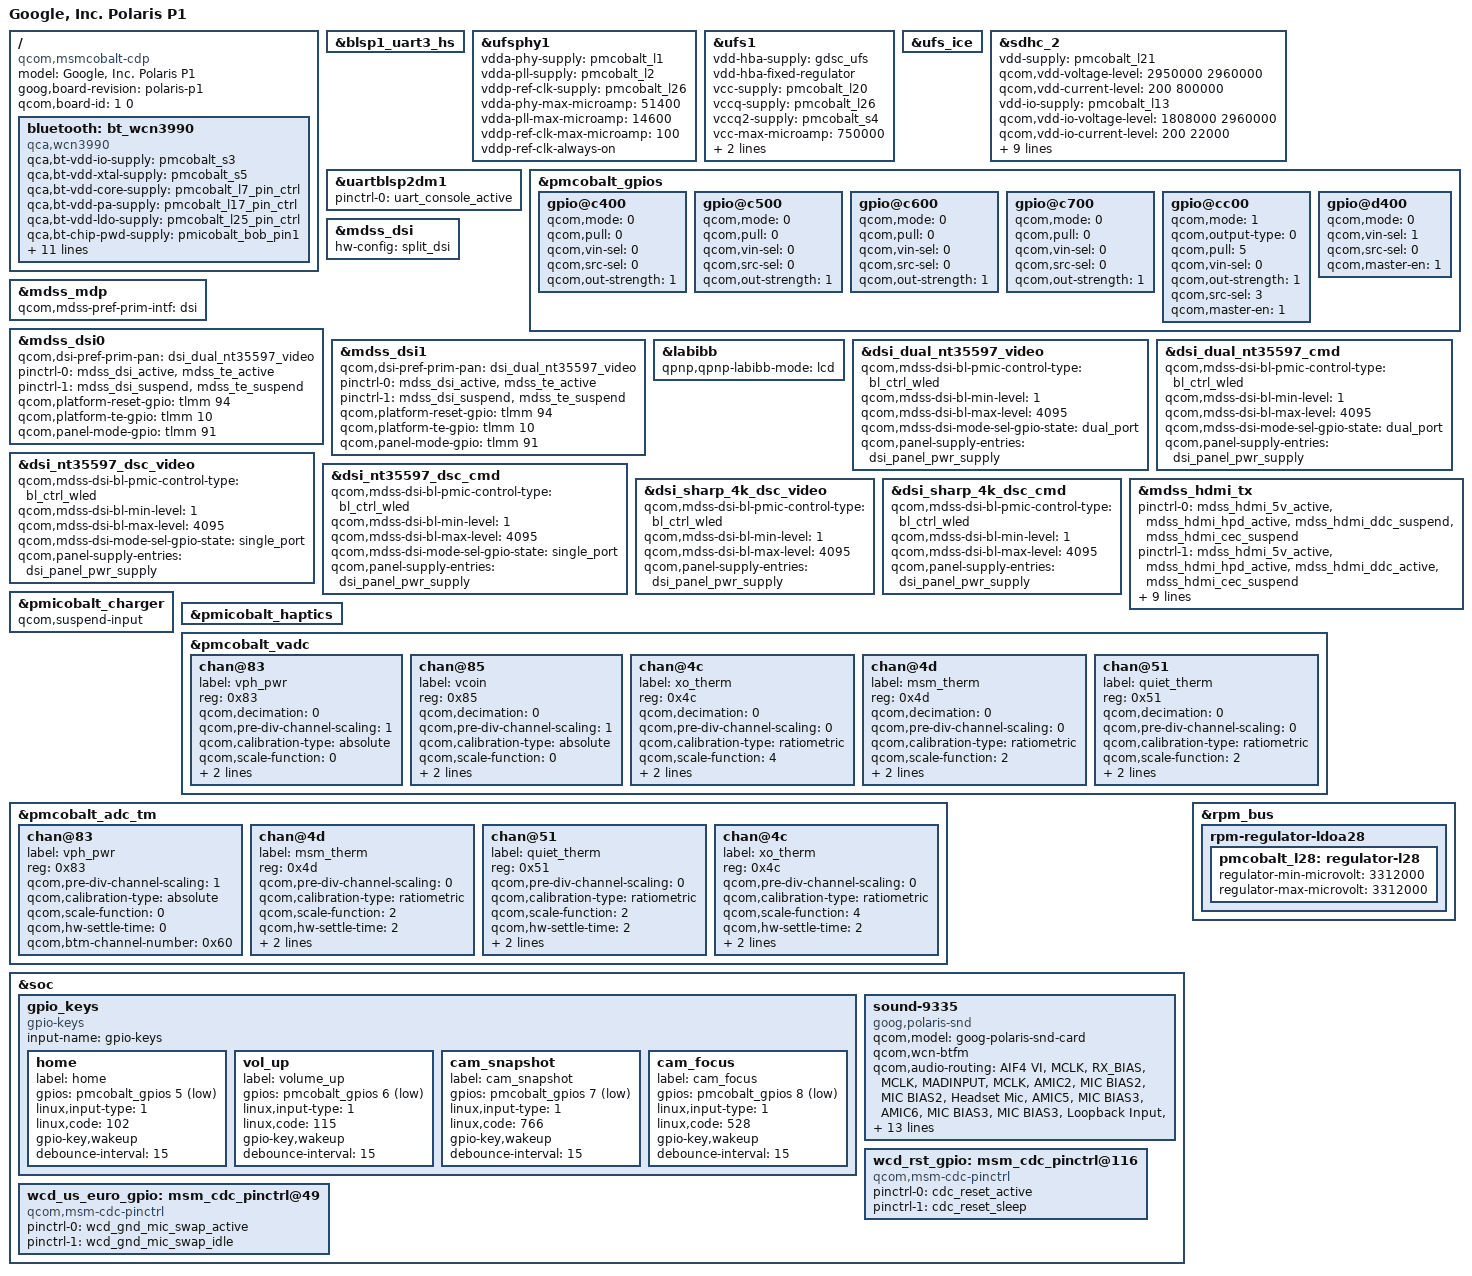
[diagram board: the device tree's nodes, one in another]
/* Copyright (c) 2016, The Linux Foundation. All rights reserved.
 *
 * This program is free software; you can redistribute it and/or modify
 * it under the terms of the GNU General Public License version 2 and
 * only version 2 as published by the Free Software Foundation.
 *
 * This program is distributed in the hope that it will be useful,
 * but WITHOUT ANY WARRANTY; without even the implied warranty of
 * MERCHANTABILITY or FITNESS FOR A PARTICULAR PURPOSE.  See the
 * GNU General Public License for more details.
 */

/dts-v1/;

#include <dt-bindings/gpio/gpio.h>
#include <dt-bindings/input/input.h>

#include "../qcom/msmcobalt.dtsi"
#include "../qcom/msmcobalt-camera-sensor-cdp.dtsi"

#include "polaris-pinctrl.dtsi"

/ {
	model = "Google, Inc. Polaris P1";
	/* compatible = "goog,polaris", "goog,polaris-p1"; */
	goog,board-revision = "polaris-p1";

	/* TODO(muirj): Remove once the boot-loader can select based
	 * on the above information only. */
	compatible = "qcom,msmcobalt-cdp", "qcom,msmcobalt", "qcom,cdp";
	qcom,board-id = <1 0>;
};

/ {
	bluetooth: bt_wcn3990 {
		compatible = "qca,wcn3990";
		qca,bt-vdd-io-supply = <&pmcobalt_s3>;
		qca,bt-vdd-xtal-supply = <&pmcobalt_s5>;
		qca,bt-vdd-core-supply = <&pmcobalt_l7_pin_ctrl>;
		qca,bt-vdd-pa-supply = <&pmcobalt_l17_pin_ctrl>;
		qca,bt-vdd-ldo-supply = <&pmcobalt_l25_pin_ctrl>;
		qca,bt-chip-pwd-supply = <&pmicobalt_bob_pin1>;

		qca,bt-vdd-io-voltage-level = <1352000 1352000>;
		qca,bt-vdd-xtal-voltage-level = <2040000 2040000>;
		qca,bt-vdd-core-voltage-level = <1800000 1800000>;
		qca,bt-vdd-pa-voltage-level = <1304000 1304000>;
		qca,bt-vdd-ldo-voltage-level = <3312000 3312000>;
		qca,bt-chip-pwd-voltage-level = <3600000 3600000>;

		qca,bt-vdd-io-current-level = <1>; /* LPM/PFM */
		qca,bt-vdd-xtal-current-level = <1>; /* LPM/PFM */
		qca,bt-vdd-core-current-level = <0>; /* LPM/PFM */
		qca,bt-vdd-pa-current-level = <0>; /* LPM/PFM */
		qca,bt-vdd-ldo-current-level = <0>; /* LPM/PFM */
	};
};

&blsp1_uart3_hs {
	status = "ok";
};

&ufsphy1 {
	vdda-phy-supply = <&pmcobalt_l1>;
	vdda-pll-supply = <&pmcobalt_l2>;
	vddp-ref-clk-supply = <&pmcobalt_l26>;
	vdda-phy-max-microamp = <51400>;
	vdda-pll-max-microamp = <14600>;
	vddp-ref-clk-max-microamp = <100>;
	vddp-ref-clk-always-on;
	status = "ok";
};

&ufs1 {
	vdd-hba-supply = <&gdsc_ufs>;
	vdd-hba-fixed-regulator;
	vcc-supply = <&pmcobalt_l20>;
	vccq-supply = <&pmcobalt_l26>;
	vccq2-supply = <&pmcobalt_s4>;
	vcc-max-microamp = <750000>;
	vccq-max-microamp = <560000>;
	vccq2-max-microamp = <750000>;
	status = "ok";
};

&ufs_ice {
	status = "ok";
};

&sdhc_2 {
	vdd-supply = <&pmcobalt_l21>;
	qcom,vdd-voltage-level = <2950000 2960000>;
	qcom,vdd-current-level = <200 800000>;

	vdd-io-supply = <&pmcobalt_l13>;
	qcom,vdd-io-voltage-level = <1808000 2960000>;
	qcom,vdd-io-current-level = <200 22000>;

	pinctrl-names = "active", "sleep";
	pinctrl-0 = <&sdc2_clk_on  &sdc2_cmd_on &sdc2_data_on &sdc2_cd_on>;
	pinctrl-1 = <&sdc2_clk_off &sdc2_cmd_off &sdc2_data_off &sdc2_cd_off>;

	qcom,clk-rates = <400000 20000000 25000000
				50000000 100000000 200000000>;
	qcom,bus-speed-mode = "SDR12", "SDR25", "SDR50", "DDR50", "SDR104";

	cd-gpios = <&tlmm 95 0x1>;

	status = "ok";
};

&uartblsp2dm1 {
	status = "ok";
	pinctrl-names = "default";
	pinctrl-0 = <&uart_console_active>;
};

&pmcobalt_gpios {
	/* GPIO 5 for Home Key */
	gpio@c400 {
		status = "okay";
		qcom,mode = <0>;
		qcom,pull = <0>;
		qcom,vin-sel = <0>;
		qcom,src-sel = <0>;
		qcom,out-strength = <1>;
	};

	/* GPIO 6 for Vol+ Key */
	gpio@c500 {
		status = "okay";
		qcom,mode = <0>;
		qcom,pull = <0>;
		qcom,vin-sel = <0>;
		qcom,src-sel = <0>;
		qcom,out-strength = <1>;
	};

	/* GPIO 7 for Snapshot Key */
	gpio@c600 {
		status = "okay";
		qcom,mode = <0>;
		qcom,pull = <0>;
		qcom,vin-sel = <0>;
		qcom,src-sel = <0>;
		qcom,out-strength = <1>;
	};

	/* GPIO 8 for Focus Key */
	gpio@c700 {
		status = "okay";
		qcom,mode = <0>;
		qcom,pull = <0>;
		qcom,vin-sel = <0>;
		qcom,src-sel = <0>;
		qcom,out-strength = <1>;
	};

	gpio@cc00 { /* GPIO 13 */
		qcom,mode = <1>;
		qcom,output-type = <0>;
		qcom,pull = <5>;
		qcom,vin-sel = <0>;
		qcom,out-strength = <1>;
		qcom,src-sel = <3>;
		qcom,master-en = <1>;
		status = "okay";
	};

	/* GPIO 21 (NFC_CLK_REQ) */
	gpio@d400 {
		qcom,mode = <0>;
		qcom,vin-sel = <1>;
		qcom,src-sel = <0>;
		qcom,master-en = <1>;
		status = "okay";
	};
};

&mdss_mdp {
	qcom,mdss-pref-prim-intf = "dsi";
};

&mdss_dsi {
	hw-config = "split_dsi";
};

&mdss_dsi0 {
	qcom,dsi-pref-prim-pan = <&dsi_dual_nt35597_video>;
	pinctrl-names = "mdss_default", "mdss_sleep";
	pinctrl-0 = <&mdss_dsi_active &mdss_te_active>;
	pinctrl-1 = <&mdss_dsi_suspend &mdss_te_suspend>;
	qcom,platform-reset-gpio = <&tlmm 94 0>;
	qcom,platform-te-gpio = <&tlmm 10 0>;
	qcom,panel-mode-gpio = <&tlmm 91 0>;
};

&mdss_dsi1 {
	qcom,dsi-pref-prim-pan = <&dsi_dual_nt35597_video>;
	pinctrl-names = "mdss_default", "mdss_sleep";
	pinctrl-0 = <&mdss_dsi_active &mdss_te_active>;
	pinctrl-1 = <&mdss_dsi_suspend &mdss_te_suspend>;
	qcom,platform-reset-gpio = <&tlmm 94 0>;
	qcom,platform-te-gpio = <&tlmm 10 0>;
	qcom,panel-mode-gpio = <&tlmm 91 0>;
};

&labibb {
	status = "ok";
	qpnp,qpnp-labibb-mode = "lcd";
};

&dsi_dual_nt35597_video {
	qcom,mdss-dsi-bl-pmic-control-type = "bl_ctrl_wled";
	qcom,mdss-dsi-bl-min-level = <1>;
	qcom,mdss-dsi-bl-max-level = <4095>;
	qcom,mdss-dsi-mode-sel-gpio-state = "dual_port";
	qcom,panel-supply-entries = <&dsi_panel_pwr_supply>;
};

&dsi_dual_nt35597_cmd {
	qcom,mdss-dsi-bl-pmic-control-type = "bl_ctrl_wled";
	qcom,mdss-dsi-bl-min-level = <1>;
	qcom,mdss-dsi-bl-max-level = <4095>;
	qcom,mdss-dsi-mode-sel-gpio-state = "dual_port";
	qcom,panel-supply-entries = <&dsi_panel_pwr_supply>;
};

&dsi_nt35597_dsc_video {
	qcom,mdss-dsi-bl-pmic-control-type = "bl_ctrl_wled";
	qcom,mdss-dsi-bl-min-level = <1>;
	qcom,mdss-dsi-bl-max-level = <4095>;
	qcom,mdss-dsi-mode-sel-gpio-state = "single_port";
	qcom,panel-supply-entries = <&dsi_panel_pwr_supply>;
};

&dsi_nt35597_dsc_cmd {
	qcom,mdss-dsi-bl-pmic-control-type = "bl_ctrl_wled";
	qcom,mdss-dsi-bl-min-level = <1>;
	qcom,mdss-dsi-bl-max-level = <4095>;
	qcom,mdss-dsi-mode-sel-gpio-state = "single_port";
	qcom,panel-supply-entries = <&dsi_panel_pwr_supply>;
};

&dsi_sharp_4k_dsc_video {
	qcom,mdss-dsi-bl-pmic-control-type = "bl_ctrl_wled";
	qcom,mdss-dsi-bl-min-level = <1>;
	qcom,mdss-dsi-bl-max-level = <4095>;
	qcom,panel-supply-entries = <&dsi_panel_pwr_supply>;
};

&dsi_sharp_4k_dsc_cmd {
	qcom,mdss-dsi-bl-pmic-control-type = "bl_ctrl_wled";
	qcom,mdss-dsi-bl-min-level = <1>;
	qcom,mdss-dsi-bl-max-level = <4095>;
	qcom,panel-supply-entries = <&dsi_panel_pwr_supply>;
};

&mdss_hdmi_tx {
	pinctrl-names = "hdmi_hpd_active", "hdmi_ddc_active", "hdmi_cec_active",
				"hdmi_active", "hdmi_sleep";
	pinctrl-0 = <&mdss_hdmi_5v_active  &mdss_hdmi_hpd_active
			&mdss_hdmi_ddc_suspend &mdss_hdmi_cec_suspend>;
	pinctrl-1 = <&mdss_hdmi_5v_active &mdss_hdmi_hpd_active
			&mdss_hdmi_ddc_active &mdss_hdmi_cec_suspend>;
	pinctrl-2 = <&mdss_hdmi_5v_active &mdss_hdmi_hpd_active
			&mdss_hdmi_cec_active &mdss_hdmi_ddc_suspend>;
	pinctrl-3 = <&mdss_hdmi_5v_active &mdss_hdmi_hpd_active
			&mdss_hdmi_ddc_active &mdss_hdmi_cec_active>;
	pinctrl-4 = <&mdss_hdmi_5v_suspend &mdss_hdmi_hpd_suspend
			&mdss_hdmi_ddc_suspend &mdss_hdmi_cec_suspend>;
};

&pmicobalt_charger {
	qcom,suspend-input;
};

&pmicobalt_haptics {
	status = "okay";
};

&pmcobalt_vadc {
	chan@83 {
		label = "vph_pwr";
		reg = <0x83>;
		qcom,decimation = <0>;
		qcom,pre-div-channel-scaling = <1>;
		qcom,calibration-type = "absolute";
		qcom,scale-function = <0>;
		qcom,hw-settle-time = <0>;
		qcom,fast-avg-setup = <0>;
	};

	chan@85 {
		label = "vcoin";
		reg = <0x85>;
		qcom,decimation = <0>;
		qcom,pre-div-channel-scaling = <1>;
		qcom,calibration-type = "absolute";
		qcom,scale-function = <0>;
		qcom,hw-settle-time = <0>;
		qcom,fast-avg-setup = <0>;
	};

	chan@4c {
		label = "xo_therm";
		reg = <0x4c>;
		qcom,decimation = <0>;
		qcom,pre-div-channel-scaling = <0>;
		qcom,calibration-type = "ratiometric";
		qcom,scale-function = <4>;
		qcom,hw-settle-time = <2>;
		qcom,fast-avg-setup = <0>;
	};

	chan@4d {
		label = "msm_therm";
		reg = <0x4d>;
		qcom,decimation = <0>;
		qcom,pre-div-channel-scaling = <0>;
		qcom,calibration-type = "ratiometric";
		qcom,scale-function = <2>;
		qcom,hw-settle-time = <2>;
		qcom,fast-avg-setup = <0>;
	};

	chan@51 {
		label = "quiet_therm";
		reg = <0x51>;
		qcom,decimation = <0>;
		qcom,pre-div-channel-scaling = <0>;
		qcom,calibration-type = "ratiometric";
		qcom,scale-function = <2>;
		qcom,hw-settle-time = <2>;
		qcom,fast-avg-setup = <0>;
	};
};

&pmcobalt_adc_tm {
	chan@83 {
		label = "vph_pwr";
		reg = <0x83>;
		qcom,pre-div-channel-scaling = <1>;
		qcom,calibration-type = "absolute";
		qcom,scale-function = <0>;
		qcom,hw-settle-time = <0>;
		qcom,btm-channel-number = <0x60>;
	};

	chan@4d {
		label = "msm_therm";
		reg = <0x4d>;
		qcom,pre-div-channel-scaling = <0>;
		qcom,calibration-type = "ratiometric";
		qcom,scale-function = <2>;
		qcom,hw-settle-time = <2>;
		qcom,btm-channel-number = <0x68>;
		qcom,thermal-node;
	};

	chan@51 {
		label = "quiet_therm";
		reg = <0x51>;
		qcom,pre-div-channel-scaling = <0>;
		qcom,calibration-type = "ratiometric";
		qcom,scale-function = <2>;
		qcom,hw-settle-time = <2>;
		qcom,btm-channel-number = <0x70>;
		qcom,thermal-node;
	};

	chan@4c {
		label = "xo_therm";
		reg = <0x4c>;
		qcom,pre-div-channel-scaling = <0>;
		qcom,calibration-type = "ratiometric";
		qcom,scale-function = <4>;
		qcom,hw-settle-time = <2>;
		qcom,btm-channel-number = <0x78>;
		qcom,thermal-node;
	};
};

&soc {
	/delete-node/ msm_cdc_pinctrl@64;
	/delete-node/ msm_cdc_pinctrl@65;
	/delete-node/ msm_cdc_pinctrl@66;
	/delete-node/ msm_cdc_pinctrl@75;

	gpio_keys {
		compatible = "gpio-keys";
		input-name = "gpio-keys";
		status = "okay";

		home {
			label = "home";
			gpios = <&pmcobalt_gpios 5 0x1>;
			linux,input-type = <1>;
			linux,code = <102>;
			gpio-key,wakeup;
			debounce-interval = <15>;

		};

		vol_up {
			label = "volume_up";
			gpios = <&pmcobalt_gpios 6 0x1>;
			linux,input-type = <1>;
			linux,code = <115>;
			gpio-key,wakeup;
			debounce-interval = <15>;
		};

		cam_snapshot {
			label = "cam_snapshot";
			gpios = <&pmcobalt_gpios 7 0x1>;
			linux,input-type = <1>;
			linux,code = <766>;
			gpio-key,wakeup;
			debounce-interval = <15>;
		};

		cam_focus {
			label = "cam_focus";
			gpios = <&pmcobalt_gpios 8 0x1>;
			linux,input-type = <1>;
			linux,code = <528>;
			gpio-key,wakeup;
			debounce-interval = <15>;
		};
	};

	sound-9335 {
		compatible = "goog,polaris-snd";
		qcom,model = "goog-polaris-snd-card";
		qcom,wcn-btfm;

		qcom,audio-routing =
			"AIF4 VI", "MCLK",
			"RX_BIAS", "MCLK",
			"MADINPUT", "MCLK",
			"AMIC2", "MIC BIAS2",
			"MIC BIAS2", "Headset Mic",
			"AMIC5", "MIC BIAS3",
			"AMIC6", "MIC BIAS3",
			"MIC BIAS3", "Loopback Input",
			"DMIC0", "MIC BIAS1",
			"MIC BIAS1", "Digital Mic0",
			"DMIC1", "MIC BIAS1",
			"MIC BIAS1", "Digital Mic1",
			"DMIC2", "MIC BIAS4",
			"MIC BIAS4", "Digital Mic2",
			"DMIC3", "MIC BIAS4",
			"MIC BIAS4", "Digital Mic3",
			"DMIC4", "MIC BIAS4",
			"MIC BIAS4", "Digital Mic4",
			"DMIC5", "MIC BIAS4",
			"MIC BIAS4", "Digital Mic5",
			"Loopback Output", "LINEOUT1",
			"Loopback Output", "LINEOUT2",
			"SpkrLeft IN", "SPK1 OUT",
			"SpkrRight IN", "SPK2 OUT";

		asoc-codec = <&stub_codec>;
		asoc-codec-names = "msm-stub-codec.1";

		qcom,msm-mbhc-hphl-swh = <1>;
		qcom,msm-mbhc-gnd-swh = <1>;
	};

	wcd_rst_gpio: msm_cdc_pinctrl@116 {
		compatible = "qcom,msm-cdc-pinctrl";
		pinctrl-names = "aud_active", "aud_sleep";
		pinctrl-0 = <&cdc_reset_active>;
		pinctrl-1 = <&cdc_reset_sleep>;
	};

	wcd_us_euro_gpio: msm_cdc_pinctrl@49 {
		compatible = "qcom,msm-cdc-pinctrl";
		pinctrl-names = "aud_active", "aud_sleep";
		pinctrl-0 = <&wcd_gnd_mic_swap_active>;
		pinctrl-1 = <&wcd_gnd_mic_swap_idle>;
	};
};

&rpm_bus {
	rpm-regulator-ldoa28 {
		status = "okay";
		pmcobalt_l28: regulator-l28 {
			regulator-min-microvolt = <3312000>;
			regulator-max-microvolt = <3312000>;
			status = "okay";
		};
	};
};
